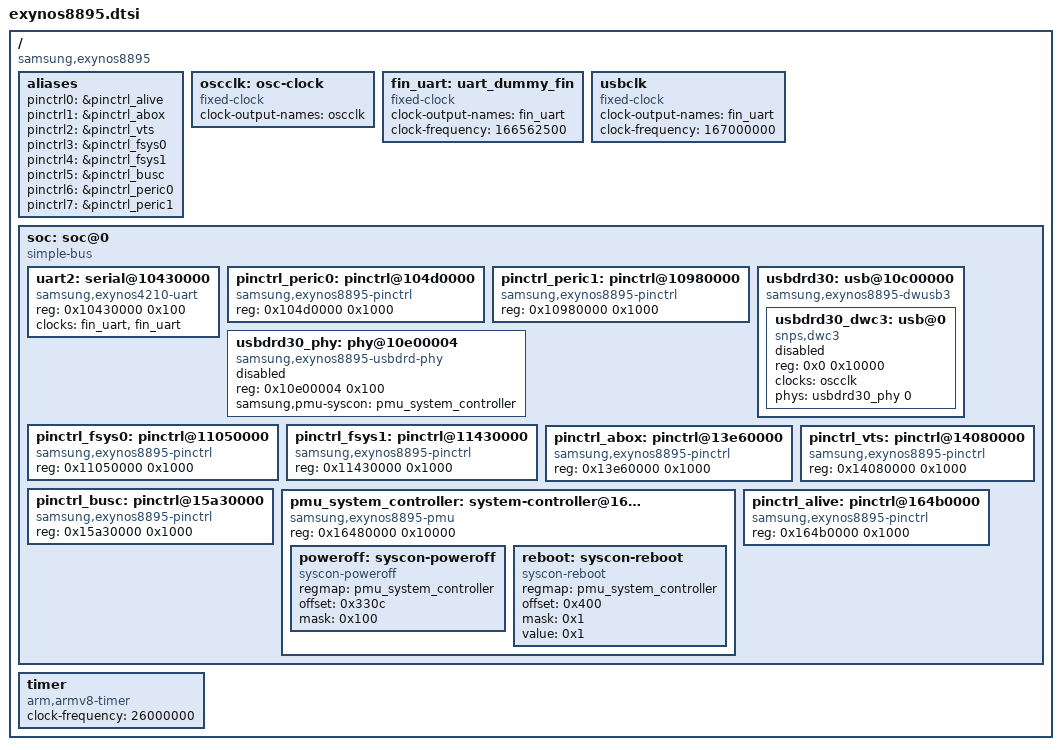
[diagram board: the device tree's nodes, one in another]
// SPDX-License-Identifier: GPL-2.0 OR BSD-3-Clause
/*
 * Samsung's Exynos 8895 SoC device tree source
 *
 * Copyright (c) 2024, Ivaylo Ivanov <ivo.ivanov.ivanov1@gmail.com>
 */

/ {
	compatible = "samsung,exynos8895";
	#address-cells = <2>;
	#size-cells = <1>;

	aliases {
		pinctrl0 = &pinctrl_alive;
		pinctrl1 = &pinctrl_abox;
		pinctrl2 = &pinctrl_vts;
		pinctrl3 = &pinctrl_fsys0;
		pinctrl4 = &pinctrl_fsys1;
		pinctrl5 = &pinctrl_busc;
		pinctrl6 = &pinctrl_peric0;
		pinctrl7 = &pinctrl_peric1;
	};

	oscclk: osc-clock {
		compatible = "fixed-clock";
		#clock-cells = <0>;
		clock-output-names = "oscclk";
	};

	/* Dummy clock for uart */
	fin_uart: uart_dummy_fin {
		compatible = "fixed-clock";
		clock-output-names = "fin_uart";
		clock-frequency = <166562500>;
		#clock-cells = <0>;
	};

	usbclk: usbclk {
		compatible = "fixed-clock";
		clock-output-names = "fin_uart";
		clock-frequency = <167000000>;
		#clock-cells = <0>;
	};

	soc: soc@0 {
		compatible = "simple-bus";
		ranges = <0x0 0x0 0x0 0x20000000>;

		#address-cells = <1>;
		#size-cells = <1>;

		uart2: serial@10430000 {
			compatible = "samsung,exynos4210-uart";
			reg = <0x10430000 0x100>;
			bootph-all;
			clocks = <&fin_uart>, <&fin_uart>; // driver uses 1st clock
			clock-names = "uart", "clk_uart_baud0";
			//pinctrl-names = "default";
			//pinctrl-0 = <&uart2_bus>;
		};

		pinctrl_peric0: pinctrl@104d0000 {
			compatible = "samsung,exynos8895-pinctrl";
			reg = <0x104d0000 0x1000>;
		};

		pinctrl_peric1: pinctrl@10980000 {
			compatible = "samsung,exynos8895-pinctrl";
			reg = <0x10980000 0x1000>;
		};

		usbdrd30: usb@10c00000 {
			compatible = "samsung,exynos8895-dwusb3";
			//clocks = <&cmu_fsys0 CLK_GOUT_FSYS0_USBTV_I_USB30DRD_ACLK>,
			//	 <&cmu_fsys0 CLK_GOUT_FSYS0_USBTV_I_USB30DRD_SUSPEND_CLK>,
			//	 <&cmu_fsys0 CLK_GOUT_FSYS0_USBTV_I_USB30DRD_REF_CLK>;
			//clock-names = "aclk", "susp_clk", "ref_clk";
			#address-cells = <1>;
			#size-cells = <1>;
			ranges = <0x0 0x10c00000 0x10000>;
			//status = "disabled";

			usbdrd30_dwc3: usb@0 {
				compatible = "snps,dwc3";
				reg = <0x0 0x10000>;
				clocks = <&oscclk>;
				clock-names = "ref";
				phys = <&usbdrd30_phy 0>;
				phy-names = "usb2-phy";
				status = "disabled";
			};
		};

		usbdrd30_phy: phy@10e00004 {
			compatible = "samsung,exynos8895-usbdrd-phy";
			reg = <0x10e00004 0x100>;
			#phy-cells = <1>;
			samsung,pmu-syscon = <&pmu_system_controller>;
			status = "disabled";
		};

		pinctrl_fsys0: pinctrl@11050000 {
			compatible = "samsung,exynos8895-pinctrl";
			reg = <0x11050000 0x1000>;
		};

		pinctrl_fsys1: pinctrl@11430000 {
			compatible = "samsung,exynos8895-pinctrl";
			reg = <0x11430000 0x1000>;
		};

		pinctrl_abox: pinctrl@13e60000 {
			compatible = "samsung,exynos8895-pinctrl";
			reg = <0x13e60000 0x1000>;
		};

		pinctrl_vts: pinctrl@14080000 {
			compatible = "samsung,exynos8895-pinctrl";
			reg = <0x14080000 0x1000>;
		};

		pinctrl_busc: pinctrl@15a30000 {
			compatible = "samsung,exynos8895-pinctrl";
			reg = <0x15a30000 0x1000>;
		};

		pmu_system_controller: system-controller@16480000 {
			compatible = "samsung,exynos8895-pmu",
				     "samsung,exynos7-pmu", "syscon";
			reg = <0x16480000 0x10000>;

			poweroff: syscon-poweroff {
				compatible = "syscon-poweroff";
				regmap = <&pmu_system_controller>;
				offset = <0x330c>; /* PMU_PS_HOLD_CONTROL */
				mask = <0x100>; /* reset value */
			};

			reboot: syscon-reboot {
				compatible = "syscon-reboot";
				regmap = <&pmu_system_controller>;
				offset = <0x400>; /* PMU_SWRESET */
				mask = <0x1>; /* SWRESET_SYSTEM */
				value = <0x1>; /* reset value */
			};
		};

		pinctrl_alive: pinctrl@164b0000 {
			compatible = "samsung,exynos8895-pinctrl";
			reg = <0x164b0000 0x1000>;
		};
	};

	timer {
		compatible = "arm,armv8-timer";
		/*
		 * Non-updatable, broken stock Samsung bootloader does not
		 * configure CNTFRQ_EL0
		 */
		clock-frequency = <26000000>;
	};
};

#include "exynos8895-pinctrl.dtsi"
